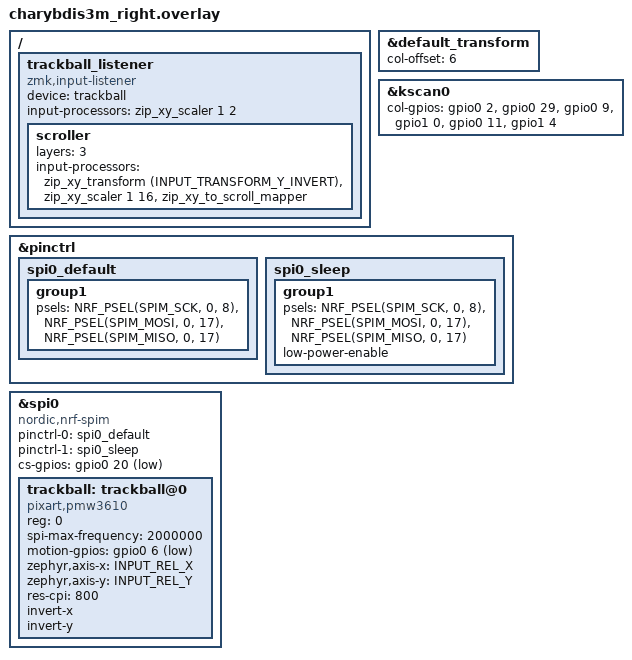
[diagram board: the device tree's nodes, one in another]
/*
 * Copyright (c) 2020 ZMK Contributors
 *
 * SPDX-License-Identifier: MIT
 */
 
#include "charybdis3m.dtsi"
#include <input/processors.dtsi>
#include <dt-bindings/zmk/input_transform.h>
#include <zephyr/dt-bindings/input/input-event-codes.h>


&default_transform {
    col-offset = <6>;
}; 

&kscan0 {
	col-gpios
		= <&gpio0 2 GPIO_ACTIVE_HIGH>
		, <&gpio0 29 GPIO_ACTIVE_HIGH>
		, <&gpio0 9 GPIO_ACTIVE_HIGH>
		, <&gpio1 0  GPIO_ACTIVE_HIGH>
		, <&gpio0 11 GPIO_ACTIVE_HIGH>
		, <&gpio1 4  GPIO_ACTIVE_HIGH>
		;
};

&pinctrl {
    spi0_default: spi0_default {
        group1 {
            psels = <NRF_PSEL(SPIM_SCK, 0, 8)>,
                <NRF_PSEL(SPIM_MOSI, 0, 17)>,
                <NRF_PSEL(SPIM_MISO, 0, 17)>;
        };
    };

    spi0_sleep: spi0_sleep {
        group1 {
            psels = <NRF_PSEL(SPIM_SCK, 0, 8)>,
                <NRF_PSEL(SPIM_MOSI, 0, 17)>,
                <NRF_PSEL(SPIM_MISO, 0, 17)>;
            low-power-enable;
        };
    };
};

&spi0 {
    compatible = "nordic,nrf-spim";
    status = "okay";
    pinctrl-0 = <&spi0_default>;
    pinctrl-1 = <&spi0_sleep>;
    pinctrl-names = "default", "sleep";
    cs-gpios = <&gpio0 20 GPIO_ACTIVE_LOW>;

    trackball: trackball@0 {
        compatible = "pixart,pmw3610";
        reg = <0>;
        spi-max-frequency = <2000000>;
        motion-gpios = <&gpio0 6 GPIO_ACTIVE_LOW>;
        zephyr,axis-x = <INPUT_REL_X>;
        zephyr,axis-y = <INPUT_REL_Y>;
        res-cpi = <800>;
        status = "okay";
	invert-x;
	invert-y;
    };
};

/ {
    trackball_listener {
        compatible = "zmk,input-listener";
        device = <&trackball>;
	input-processors = <&zip_xy_scaler 1 2>;
	scroller {
		layers = <3>;
		input-processors = <&zip_xy_transform (INPUT_TRANSFORM_Y_INVERT)>, <&zip_xy_scaler 1 16>, <&zip_xy_to_scroll_mapper>;

	};
    };
};
